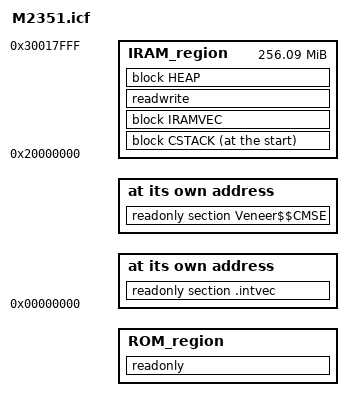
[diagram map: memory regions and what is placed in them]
include partition_M2351_sub

/*###ICF### Section handled by ICF editor, don't touch! ****/
/*-Editor annotation file-*/
/* IcfEditorFile="$TOOLKIT_DIR$\config\ide\IcfEditor\cortex_v1_0.xml" */

if (isdefinedsymbol(__DOMAIN_NS)) {

    if (! isdefinedsymbol(MBED_APP_START)) {
        define symbol MBED_APP_START                = 0x10000000 + NU_TZ_SECURE_FLASH_SIZE;
    }

    if (! isdefinedsymbol(MBED_APP_SIZE)) {
        define symbol MBED_APP_SIZE                 = 0x80000 - NU_TZ_SECURE_FLASH_SIZE;
    }


    /*-Specials-*/
    define symbol __ICFEDIT_intvec_start__ = MBED_APP_START;
    /*-Memory Regions-*/
    define symbol __ICFEDIT_region_ROM_start__      = MBED_APP_START;
    define symbol __ICFEDIT_region_ROM_end__        = MBED_APP_START + MBED_APP_SIZE - 1;
    define symbol __ICFEDIT_region_IRAM_start__     = 0x30000000 + NU_TZ_SECURE_SRAM_SIZE;
    define symbol __ICFEDIT_region_IRAM_end__       = 0x30018000 - 1;
    
    /*-Sizes-*/
    define symbol __ICFEDIT_size_cstack__           = 0x800;
    define symbol __ICFEDIT_size_heap__             = 0x8000;

} else {

    if (! isdefinedsymbol(MBED_APP_START)) {
        define symbol MBED_APP_START = 0;
    }

    if (! isdefinedsymbol(MBED_APP_SIZE)) {
        define symbol MBED_APP_SIZE                 = NU_TZ_SECURE_FLASH_SIZE;
    }
    
    /* Requirements for NSC location
     *
     * 1. By IDAU, 0~0x4000 is secure. NSC can only locate in 0x4000~0x10000000.
     * 2. Greentea flash IAP uses last 4 sectors for its test. Avoid this range.
     * 3. Greentea NVSTORE uses last 2 sectors or 4KB x 2 for its test. Avoid this range.
     */
    define exported symbol NU_TZ_NSC_REGION_BASE    = MBED_APP_START + MBED_APP_SIZE - 0x2000 - NU_TZ_NSC_REGION_SIZE;

    /*-Specials-*/
    define symbol __ICFEDIT_intvec_start__          = MBED_APP_START;
    /*-Memory Regions-*/
    define symbol __ICFEDIT_region_ROM_start__      = MBED_APP_START;
    define symbol __ICFEDIT_region_ROM_end__        = MBED_APP_START + MBED_APP_SIZE - 1;
    define symbol __ICFEDIT_region_NSCROM_start__   = NU_TZ_NSC_REGION_BASE;
    define symbol __ICFEDIT_region_NSCROM_end__     = NU_TZ_NSC_REGION_BASE + NU_TZ_NSC_REGION_SIZE - 1;
    define symbol __ICFEDIT_region_IRAM_start__     = 0x20000000;
    define symbol __ICFEDIT_region_IRAM_end__       = 0x20000000 + NU_TZ_SECURE_SRAM_SIZE - 1;

    export symbol __NU_TZ_SECURE_FLASH_SIZE__       = NU_TZ_SECURE_FLASH_SIZE;
    export symbol __NU_TZ_SECURE_SRAM_SIZE__        = NU_TZ_SECURE_SRAM_SIZE;
    export symbol __NU_TZ_NSC_REGION_BASE__         = NU_TZ_NSC_REGION_BASE;
    export symbol __NU_TZ_NSC_REGION_SIZE__         = NU_TZ_NSC_REGION_SIZE;

    /*-Sizes-*/
    define symbol __ICFEDIT_size_cstack__           = 0x800;
    define symbol __ICFEDIT_size_heap__             = 0x4000;
}

/**** End of ICF editor section. ###ICF###*/


define memory mem with size = 4G;
define region ROM_region   = mem:[from __ICFEDIT_region_ROM_start__   to __ICFEDIT_region_ROM_end__];
define region IRAM_region  = mem:[from __ICFEDIT_region_IRAM_start__  to __ICFEDIT_region_IRAM_end__];

define block CSTACK    with alignment = 8, size = __ICFEDIT_size_cstack__   { };
define block HEAP      with alignment = 8, size = __ICFEDIT_size_heap__     { };
/* NOTE: Vector table base requires to be aligned to the power of vector table size. Give a safe value here. */
define block IRAMVEC   with alignment = 1024, size = 4 * (16 + 102)          { };


initialize by copy { readwrite };
do not initialize  { section .noinit };

place at address mem:__ICFEDIT_intvec_start__ { readonly section .intvec };

place in ROM_region   { readonly };
if (! isdefinedsymbol(__DOMAIN_NS)) {
    place at address mem:__ICFEDIT_region_NSCROM_start__ { readonly section Veneer$$CMSE };
}
place at start of IRAM_region   { block CSTACK };
place in IRAM_region   { block IRAMVEC };
place in IRAM_region   { readwrite };
place in IRAM_region   { block HEAP };
